# AT32F425xx_v2 register map
Vendor: Keil; Series: AT32F425; File version: 1.0
CPU: CM4 r0p1, little endian, no MPU, FPU, 4 interrupt priority bits
Registers are 32-bit, read-write, reset 0x0 unless marked. A register's access mark holds for its fields unless they carry their own. Offsets are from the block's base; [hi:lo] are bit positions; {n}, {i} and the like mark numbered series.

## SCFG — System configuration controller
Base 0x40010000
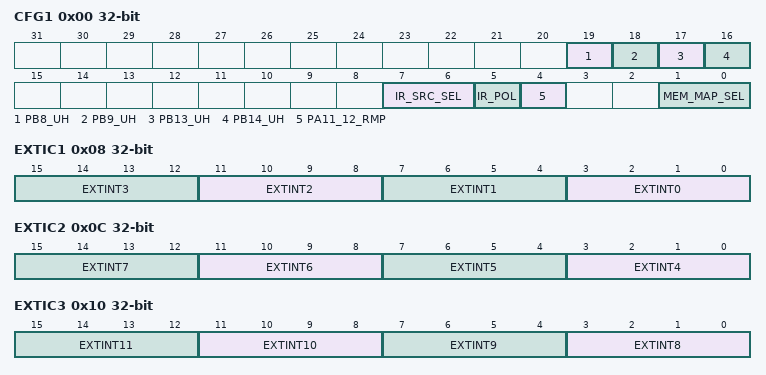
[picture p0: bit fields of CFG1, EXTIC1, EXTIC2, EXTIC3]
0x00 CFG1 — configuration register 1
  [19] PB8_UH — PB8 Ultra high sourcing/sinking strength
  [18] PB9_UH — PB9 Ultra high sourcing/sinking strength
  [17] PB13_UH — PB13 Ultra high sourcing/sinking strength
  [16] PB14_UH — PB14 Ultra high sourcing/sinking strength
  [7:6] IR_SRC_SEL — Infrared modulation envelope signal source selection
  [5] IR_POL — Infrared output polarity selection
  [4] PA11_12_RMP — PA11/PA12 pins remapping bit
  [1:0] MEM_MAP_SEL — Memory mapping selection bits
0x08 EXTIC1 — external interrupt configuration register 1
  [4n+3:4n] EXTINT{n} (n=0..3) — EXTINT {n} configuration bits
0x0C EXTIC2 — external interrupt configuration register 2
  [4n-13:4n-16] EXTINT{n} (n=4..7) — EXTINT {n} configuration bits
0x10 EXTIC3 — external interrupt configuration register 3
  [4n-29:4n-32] EXTINT{n} (n=8..11) — EXTINT {n} configuration bits
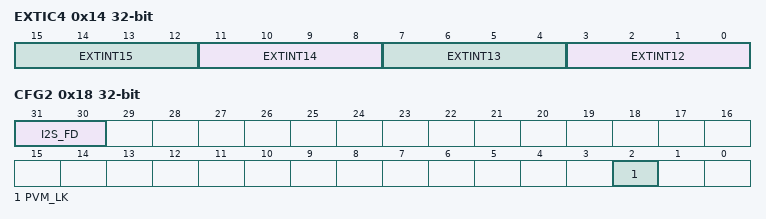
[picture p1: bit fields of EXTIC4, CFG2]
0x14 EXTIC4 — external interrupt configuration register 4
  [4n-45:4n-48] EXTINT{n} (n=12..15) — EXTINT {n} configuration bits
0x18 CFG2 — configuration register 2
  [31:30] I2S_FD — I2S full duplex
  [2] PVM_LK — PVM lock enable

## DEBUG — Debug support
Base 0xE0042000
0x00 IDCODE ro — DEBUG_IDCODE
  [31:0] PID
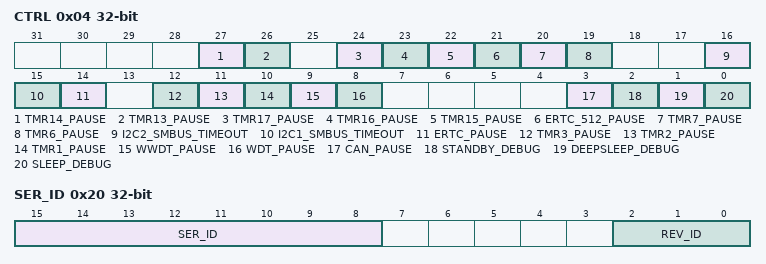
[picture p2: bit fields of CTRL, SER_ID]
0x04 CTRL — DEBUG_CTRL
  [27] TMR14_PAUSE, [26] TMR13_PAUSE, [24] TMR17_PAUSE, [23] TMR16_PAUSE, [22] TMR15_PAUSE, [21] ERTC_512_PAUSE, [20] TMR7_PAUSE, [19] TMR6_PAUSE, [16] I2C2_SMBUS_TIMEOUT, [15] I2C1_SMBUS_TIMEOUT, [14] ERTC_PAUSE, [12] TMR3_PAUSE, [11] TMR2_PAUSE, [10] TMR1_PAUSE, [9] WWDT_PAUSE, [8] WDT_PAUSE, [3] CAN_PAUSE, [2] STANDBY_DEBUG, [1] DEEPSLEEP_DEBUG, [0] SLEEP_DEBUG
0x20 SER_ID ro — SERIES ID
  [15:8] SER_ID — series ID
  [2:0] REV_ID — version ID

## CRC — CRC calculation unit
Base 0x40023000
0x00 DT reset 0xFFFFFFFF — Data register
  [31:0] DT — Data Register
0x04 CDT — Common data register
  [0] CDT — Common Data
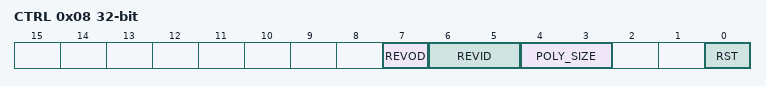
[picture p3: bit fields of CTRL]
0x08 CTRL — Control register
  [7] REVOD — Reverse output data
  [6:5] REVID — Reverse input data
  [4:3] POLY_SIZE — Polynomial size
  [0] RST — Reset bit
0x10 IDT reset 0xFFFFFFFF — Initial data register
  [31:0] IDT — Initial Data
0x14 POLY reset 0x4C11DB7 — Polynomial coefficient register
  [31:0] POLY — polynomial coefficient

## FLASH — Flash memory controler
Base 0x40022000
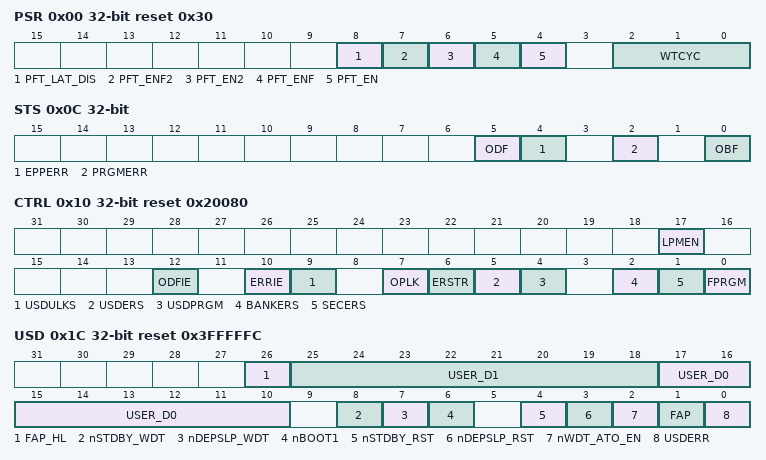
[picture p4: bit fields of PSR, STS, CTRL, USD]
0x00 PSR reset 0x30 — Performance selection register
  [8] PFT_LAT_DIS — Prefetch latency disable
  [7] PFT_ENF2 ro — Prefetch enabled flag 2
  [6] PFT_EN2 — Prefetch enable 2
  [5] PFT_ENF ro — Prefetch enabled flag
  [4] PFT_EN — Prefetch enable
  [2:0] WTCYC — Wait cycle
0x04 UNLOCK wo
  [31:0] UKVAL — Unlock key value
0x08 USD_UNLOCK wo
  [31:0] USD_UKVAL — User system data Unlock key value
0x0C STS — Status register
  [5] ODF — Operate done flag
  [4] EPPERR — Erase/program protection error
  [2] PRGMERR — program error
  [0] OBF ro — Operate busy flag
0x10 CTRL reset 0x20080 — Control register
  [17] LPMEN — Low power mode enable
  [12] ODFIE — Operation done flag interrupt enable
  [10] ERRIE — Error interrupt enable
  [9] USDULKS — User system data unlock success
  [7] OPLK — Operation lock
  [6] ERSTR — Erasing start
  [5] USDERS — User system data erase
  [4] USDPRGM — User system data program
  [2] BANKERS — Bank erase
  [1] SECERS — Sector erase
  [0] FPRGM — Flash program
0x14 ADDR wo — Address register
  [31:0] FA — Flash Address
0x1C USD ro reset 0x3FFFFFC — User system data register
  [26] FAP_HL — FAP high level
  [25:18] USER_D1 — User data 1
  [17:10] USER_D0 — User data 0
  [8] nSTDBY_WDT — Standby wdt stop count
  [7] nDEPSLP_WDT — Deepsleep wdt stop count
  [6] nBOOT1 — boot1
  [4] nSTDBY_RST — Standby reset
  [3] nDEPSLP_RST — Deepsleep reset
  [2] nWDT_ATO_EN — WDT auto enable
  [1] FAP — FLASH access protection
  [0] USDERR — User system data error
0x20 EPPS ro reset 0xFFFFFFFF — Erase/program protection status register
  [31:0] EPPS — Erase/program protection status
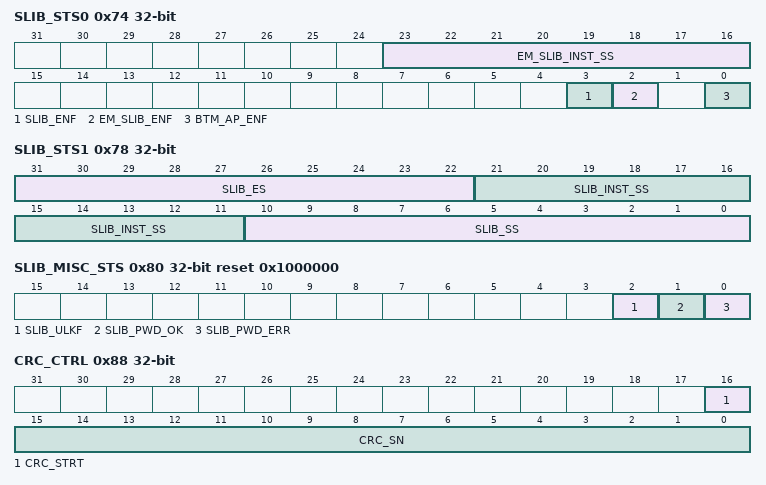
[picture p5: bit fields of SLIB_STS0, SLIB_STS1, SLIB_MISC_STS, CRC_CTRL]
0x74 SLIB_STS0 — sLib status 0 register
  [23:16] EM_SLIB_INST_SS — Extension memory sLib instruction start sector
  [3] SLIB_ENF — sLib enabled flag
  [2] EM_SLIB_ENF — Extension memory sLib enabled flag
  [0] BTM_AP_ENF — Boot memory store application code enabled flag
0x78 SLIB_STS1 — sLib status 1 register
  [31:22] SLIB_ES — sLib end sector
  [21:11] SLIB_INST_SS — sLib instruction start sector
  [10:0] SLIB_SS — sLib start sector
0x7C SLIB_PWD_CLR wo — SLIB password clear register
  [31:0] SLIB_PCLR_VAL — sLib password clear value
0x80 SLIB_MISC_STS reset 0x1000000 — sLib misc status register
  [2] SLIB_ULKF ro — sLib unlock flag
  [1] SLIB_PWD_OK ro — sLib password ok
  [0] SLIB_PWD_ERR ro — sLib password error
0x84 CRC_ADDR wo — Flash CRC data start address register
  [31:0] CRC_ADDR — CRC address
0x88 CRC_CTRL — Flash CRC controll register
  [16] CRC_STRT wo — CRC start
  [15:0] CRC_SN — CRC sector numbler
0x8C CRC_CHKR ro — FLASH CRC check result register
  [31:0] FCRC_OUT — CRC32 verification result of flash user code or SLIB code
0x160 SLIB_SET_PWD wo — sLib password setting register
  [31:0] SLIB_PSET_VAL — sLib password setting val
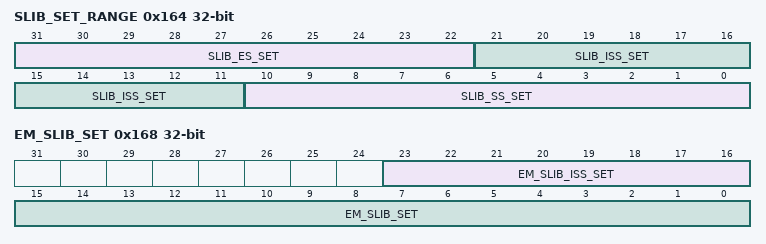
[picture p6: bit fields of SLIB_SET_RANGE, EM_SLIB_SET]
0x164 SLIB_SET_RANGE wo — Configure sLib range register
  [31:22] SLIB_ES_SET — sLib end sector setting
  [21:11] SLIB_ISS_SET — sLib instruction start sector setting
  [10:0] SLIB_SS_SET — sLib start sector setting
0x168 EM_SLIB_SET wo — Extension momery slib set register
  [23:16] EM_SLIB_ISS_SET — Extension memory sLib instruction start sector setting
  [15:0] EM_SLIB_SET — Extension memory sLib setting
0x16C BTM_MODE_SET wo — Boot memory mode setting register
  [7:0] BTM_MODE_SET — Boot memory mode setting
0x170 SLIB_UNLOCK wo
  [31:0] SLIB_UKVAL — sLib unlock key value
